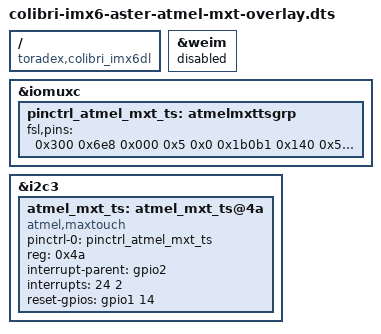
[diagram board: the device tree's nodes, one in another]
// Atmel touchscreen for the 7inch capacitive display orderable at Toradex. Use this devicetree on the Aster board.

/dts-v1/;
/plugin/;

/ {
	compatible = "toradex,colibri_imx6dl";
	fragment@0 {
		target = <&weim>;
		__overlay__{
			status = "disabled";
		};
	};
	fragment@1 {
		target = <&iomuxc>;
		__overlay__ {
			pinctrl_atmel_mxt_ts: atmelmxttsgrp {
				fsl,pins = <
					0x300 0x6e8 0x000 0x5 0x0	0x1b0b1
					0x140 0x510 0x000 0x5 0x0	0x1b0b1
				>;
			};
		};
	};
	fragment@2 {
		target = <&i2c3>;
		__overlay__ {
			atmel_mxt_ts: atmel_mxt_ts@4a {
				pinctrl-names = "default";
				pinctrl-0 = <&pinctrl_atmel_mxt_ts>;
				compatible = "atmel,maxtouch";
				reg = <0x4a>;
				interrupt-parent = <&gpio2>;
				interrupts = <24 2>;
				reset-gpios = <&gpio1 14 0>;
				status = "okay";
			};
		};
	};
};
